# ADuCM4050 register map
Vendor: Analog Devices; Series: ADuCM4050; File version: 1p0
CPU: CM4 r0p1, little endian, MPU, FPU, 3 interrupt priority bits
Registers are 32-bit, read-write, reset 0x0 unless marked. A register's access mark holds for its fields unless they carry their own. Offsets are from the block's base; [hi:lo] are bit positions; 'fields as' and 'values as' point back to an identical list.

## SYS — System Identification and Debug Enable
Base 0x40002000
0x20 ADIID 16-bit reset 0x4144 — ADI Identification
  [15:0] VALUE ro — Reads a fixed value of 0x4144 to indicate to debuggers that they are connected to an Analog Devices implemented Cortex based part
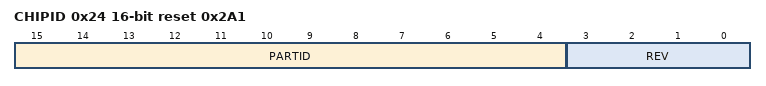
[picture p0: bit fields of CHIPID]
0x24 CHIPID 16-bit reset 0x2A1 — Chip Identifier
  [15:4] PARTID ro — Part identifier
  [3:0] REV ro — Silicon revision
0x40 SWDEN 16-bit reset 0x7072 — Serial Wire Debug Enable
  [15:0] VALUE wo range 0x00000000..0x0000FFFF — To enable SWD interface

## WDT0 — Watchdog Timer
Base 0x40002C00
0x00 LOAD 16-bit reset 0x1000 — Load Value
  [15:0] VALUE range 0x00000000..0x0000FFFF
0x04 CCNT 16-bit reset 0x1000 — Current Count Value
  [15:0] VALUE ro
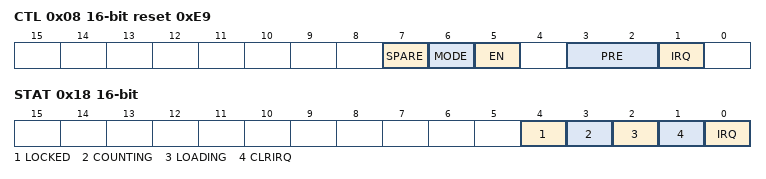
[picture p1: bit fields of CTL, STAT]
0x08 CTL 16-bit reset 0xE9 — Control
  [7] SPARE range 0x00000000..0x00000001 — Unused Spare Bit
  [6] MODE — Timer Mode
    0=FREE_RUN (Free running mode); 1=PERIODIC (Periodic mode)
  [5] EN — Timer Enable
    0=WDT_DIS (WDT not enabled); 1=WDT_EN (WDT enabled)
  [3:2] PRE — Prescaler
    0=div1 (Source clock/1); 1=div16 (Source clock/16); 2=div256 (Source clock/256 (default))
  [1] IRQ — Timer Interrupt
    0=RST (WDT asserts reset when timed out); 1=INT (WDT generates interrupt when timed out)
0x0C RESTART 16-bit — Clear Interrupt
  [15:0] CLRWORD wo range 0x00000000..0x0000FFFF — Clear Watchdog
0x18 STAT 16-bit — Status
  [4] LOCKED ro — Lock Status Bit
  [3] COUNTING ro — Control Register Write Sync in Progress
    0=COUNT_MATCH (APB and WDT clock domain CTRL values match); 1=COUNT_SYNCING (APB CTRL register values are being synchronized to WDT clock domain.)
  [2] LOADING ro — Load Register Write Sync in Progress
    0=LOAD_MATCH (APB and WDT clock domains LOAD values match.); 1=LOAD_SYNCING (APB LOAD value is being synchronized to WDT clock domain.)
  [1] CLRIRQ ro — Clear Interrupt Register Write Sync in Progress
  [0] IRQ ro — WDT Interrupt

## BEEP0 — Beeper Driver
Base 0x40005C00
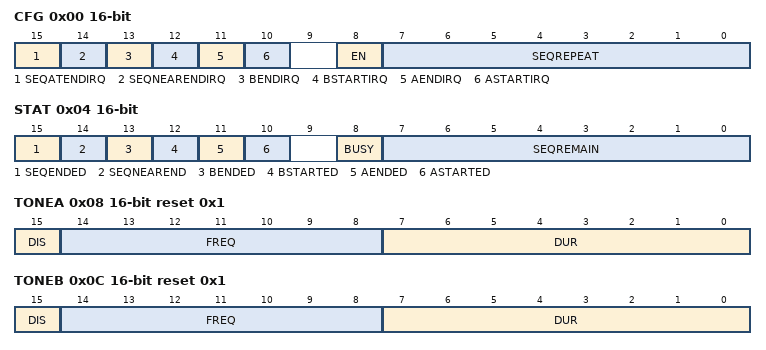
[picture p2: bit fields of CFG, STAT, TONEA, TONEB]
0x00 CFG 16-bit — Beeper Configuration
  [15] SEQATENDIRQ — Sequence End IRQ
  [14] SEQNEARENDIRQ — Sequence 1 Cycle from End IRQ
  [13] BENDIRQ — Tone B End IRQ
  [12] BSTARTIRQ — Tone B Start IRQ
  [11] AENDIRQ — Tone A End IRQ
  [10] ASTARTIRQ — Tone A Start IRQ
  [8] EN wo — Beeper Enable
  [7:0] SEQREPEAT — Beeper Sequence Repeat Value
0x04 STAT 16-bit — Beeper Status
  [15] SEQENDED range 0x00000000..0x00000001 — Sequencer Has Ended
  [14] SEQNEAREND range 0x00000000..0x00000001 — Sequencer Last Tone-pair Has Started
  [13] BENDED range 0x00000000..0x00000001 — Tone B Has Ended
  [12] BSTARTED range 0x00000000..0x00000001 — Tone B Has Started
  [11] AENDED range 0x00000000..0x00000001 — Tone A Has Ended
  [10] ASTARTED range 0x00000000..0x00000001 — Tone A Has Started
  [8] BUSY ro — Beeper is Busy
  [7:0] SEQREMAIN ro — Remaining Tone-pair Iterations to Play in Sequence Mode
0x08 TONEA 16-bit reset 0x1 — Tone A Data
  [15] DIS — Output Disable
  [14:8] FREQ — Tone Frequency
  [7:0] DUR — Tone Duration
0x0C TONEB 16-bit reset 0x1 — Tone B Data
  fields as TONEA

## DMA0 — DMA
Base 0x40010000
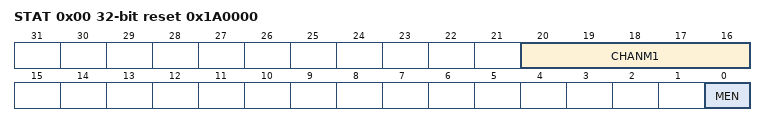
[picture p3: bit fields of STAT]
0x00 STAT reset 0x1A0000 — DMA Status
  [20:16] CHANM1 ro — Number of Available DMA Channels Minus 1
  [0] MEN ro — Enable Status of the Controller
0x04 CFG — DMA Configuration
  [0] MEN wo — Controller Enable
0x08 PDBPTR — DMA Channel Primary Control Database Pointer
  [31:0] ADDR range 0x00000000..0xFFFFFFFF — Pointer to the Base Address of the Primary Data Structure
0x0C ADBPTR reset 0x200 — DMA Channel Alternate Control Database Pointer
  [31:0] ADDR ro — Base Address of the Alternate Data Structure
0x14 SWREQ — DMA Channel Software Request
  [26:0] CHAN wo range 0x00000000..0x07FFFFFF — Generate Software Request
0x20 RMSK_SET — DMA Channel Request Mask Set
  [26:0] CHAN range 0x00000000..0x07FFFFFF — Mask Requests from DMA Channels
0x24 RMSK_CLR — DMA Channel Request Mask Clear
  [26:0] CHAN wo range 0x00000000..0x07FFFFFF — Clear Request Mask Set Bits
0x28 EN_SET — DMA Channel Enable Set
  [26:0] CHAN range 0x00000000..0x07FFFFFF — Enable DMA Channels
0x2C EN_CLR — DMA Channel Enable Clear
  [26:0] CHAN wo range 0x00000000..0x07FFFFFF — Disable DMA Channels
0x30 ALT_SET — DMA Channel Primary Alternate Set
  [26:0] CHAN range 0x00000000..0x07FFFFFF — Control Structure Status / Select Alternate Structure
0x34 ALT_CLR — DMA Channel Primary Alternate Clear
  [26:0] CHAN wo range 0x00000000..0x07FFFFFF — Select Primary Data Structure
0x38 PRI_SET — DMA Channel Priority Set
  [26:0] CHAN wo range 0x00000000..0x07FFFFFF — Configure Channel for High Priority
0x3C PRI_CLR — DMA Channel Priority Clear
  [26:0] CHPRICLR wo range 0x00000000..0x07FFFFFF — Configure Channel for Default Priority Level
0x48 ERRCHNL_CLR — DMA per Channel Error Clear
  [26:0] CHAN range 0x00000000..0x07FFFFFF — Per Channel Bus Error Status/Clear
0x4C ERR_CLR — DMA Bus Error Clear
  [26:0] CHAN range 0x00000000..0x07FFFFFF — Bus Error Status
0x50 INVALIDDESC_CLR — DMA per Channel Invalid Descriptor Clear
  [26:0] CHAN range 0x00000000..0x07FFFFFF — Per Channel Invalid Descriptor Status/Clear
0x800 BS_SET — DMA Channel Bytes Swap Enable Set
  [26:0] CHAN range 0x00000000..0x07FFFFFF — Byte Swap Status
0x804 BS_CLR — DMA Channel Bytes Swap Enable Clear
  [26:0] CHAN wo range 0x00000000..0x07FFFFFF — Disable Byte Swap
0x810 SRCADDR_SET — DMA Channel Source Address Decrement Enable Set
  [26:0] CHAN range 0x00000000..0x07FFFFFF — Source Address Decrement Status
0x814 SRCADDR_CLR — DMA Channel Source Address Decrement Enable Clear
  [26:0] CHAN wo range 0x00000000..0x07FFFFFF — Disable Source Address Decrement
0x818 DSTADDR_SET — DMA Channel Destination Address Decrement Enable Set
  [26:0] CHAN range 0x00000000..0x07FFFFFF — Destination Address Decrement Status
0x81C DSTADDR_CLR — DMA Channel Destination Address Decrement Enable Clear
  [26:0] CHAN wo range 0x00000000..0x07FFFFFF — Disable Destination Address Decrement
0xFE0 REVID reset 0x2 — DMA Controller Revision ID
  [7:0] VALUE ro
